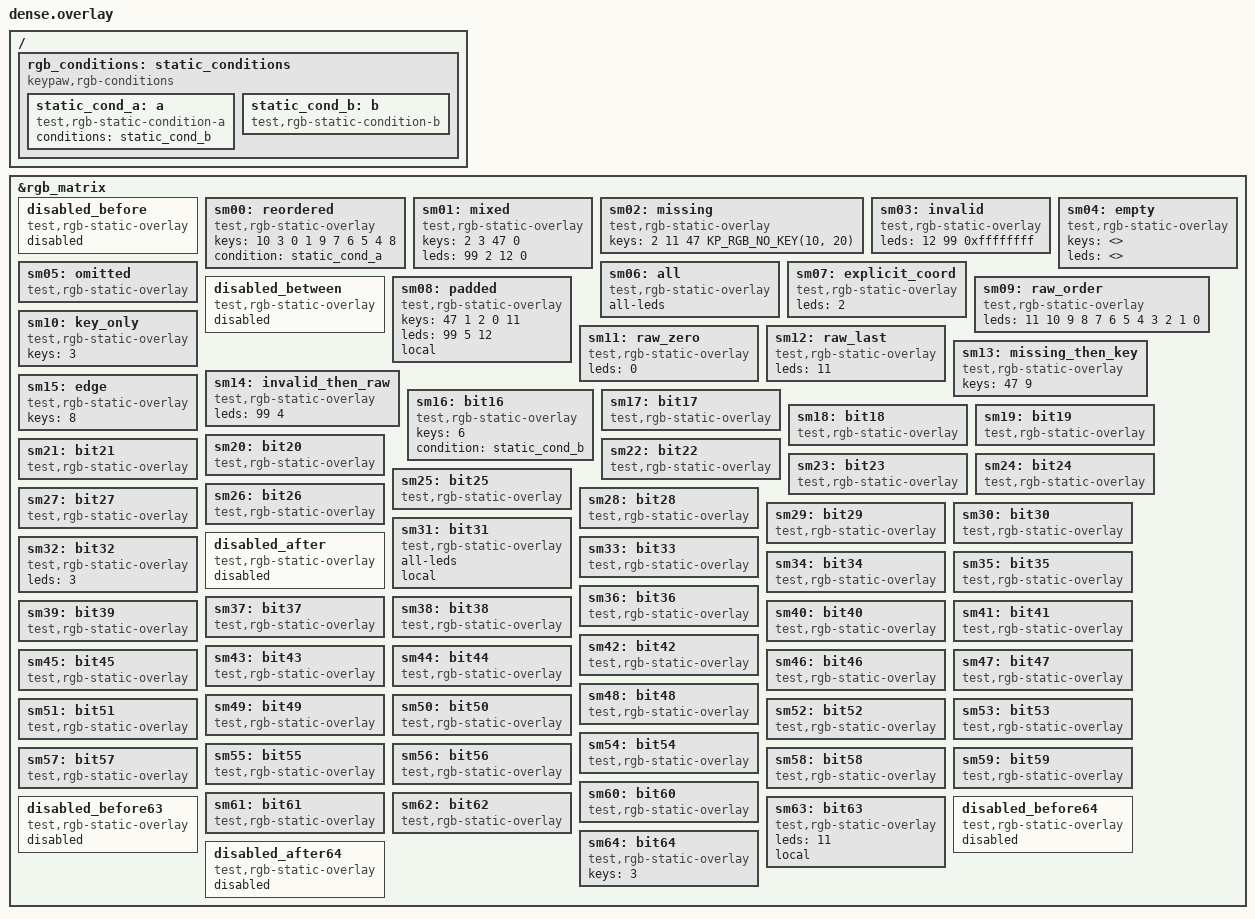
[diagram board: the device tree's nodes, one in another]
/* SPDX-License-Identifier: MIT */
#include "base.overlay"
/ {
    rgb_conditions: static_conditions {
        compatible = "keypaw,rgb-conditions";
        static_cond_a: a { compatible = "test,rgb-static-condition-a"; conditions = <&static_cond_b>; };
        static_cond_b: b { compatible = "test,rgb-static-condition-b"; };
    };
};
&rgb_matrix {
    disabled_before { compatible = "test,rgb-static-overlay"; status = "disabled"; };
    sm00: reordered { compatible = "test,rgb-static-overlay";
        keys = <10 3 0 1 9 7 6 5 4 8>; condition = <&static_cond_a>; };
    sm01: mixed { compatible = "test,rgb-static-overlay";
        keys = <2 3 47 0>; leds = <99 2 12 0>; };
    sm02: missing { compatible = "test,rgb-static-overlay"; keys = <2 11 47 KP_RGB_NO_KEY(10, 20)>; };
    sm03: invalid { compatible = "test,rgb-static-overlay"; leds = <12 99 0xffffffff>; };
    sm04: empty { compatible = "test,rgb-static-overlay"; keys = <>; leds = <>; };
    sm05: omitted { compatible = "test,rgb-static-overlay"; };
    sm06: all { compatible = "test,rgb-static-overlay"; all-leds; };
    sm07: explicit_coord { compatible = "test,rgb-static-overlay"; leds = <2>; };
    disabled_between { compatible = "test,rgb-static-overlay"; status = "disabled"; };
    sm08: padded { compatible = "test,rgb-static-overlay";
        keys = <47 1 2 0 11>; leds = <99 5 12>; local; };
    sm09: raw_order { compatible = "test,rgb-static-overlay";
        leds = <11 10 9 8 7 6 5 4 3 2 1 0>; };
    sm10: key_only { compatible = "test,rgb-static-overlay"; keys = <3>; };
    sm11: raw_zero { compatible = "test,rgb-static-overlay"; leds = <0>; };
    sm12: raw_last { compatible = "test,rgb-static-overlay"; leds = <11>; };
    sm13: missing_then_key { compatible = "test,rgb-static-overlay"; keys = <47 9>; };
    sm14: invalid_then_raw { compatible = "test,rgb-static-overlay"; leds = <99 4>; };
    sm15: edge { compatible = "test,rgb-static-overlay"; keys = <8>; };
    sm16: bit16 { compatible = "test,rgb-static-overlay";
        keys = <6>; condition = <&static_cond_b>; };
    sm17: bit17 { compatible = "test,rgb-static-overlay"; };
    sm18: bit18 { compatible = "test,rgb-static-overlay"; };
    sm19: bit19 { compatible = "test,rgb-static-overlay"; };
    sm20: bit20 { compatible = "test,rgb-static-overlay"; };
    sm21: bit21 { compatible = "test,rgb-static-overlay"; };
    sm22: bit22 { compatible = "test,rgb-static-overlay"; };
    sm23: bit23 { compatible = "test,rgb-static-overlay"; };
    sm24: bit24 { compatible = "test,rgb-static-overlay"; };
    sm25: bit25 { compatible = "test,rgb-static-overlay"; };
    sm26: bit26 { compatible = "test,rgb-static-overlay"; };
    sm27: bit27 { compatible = "test,rgb-static-overlay"; };
    sm28: bit28 { compatible = "test,rgb-static-overlay"; };
    sm29: bit29 { compatible = "test,rgb-static-overlay"; };
    sm30: bit30 { compatible = "test,rgb-static-overlay"; };
    sm31: bit31 { compatible = "test,rgb-static-overlay"; all-leds; local; };
    disabled_after { compatible = "test,rgb-static-overlay"; status = "disabled"; };
    sm32: bit32 { compatible = "test,rgb-static-overlay"; leds = <3>; };
    sm33: bit33 { compatible = "test,rgb-static-overlay"; };
    sm34: bit34 { compatible = "test,rgb-static-overlay"; };
    sm35: bit35 { compatible = "test,rgb-static-overlay"; };
    sm36: bit36 { compatible = "test,rgb-static-overlay"; };
    sm37: bit37 { compatible = "test,rgb-static-overlay"; };
    sm38: bit38 { compatible = "test,rgb-static-overlay"; };
    sm39: bit39 { compatible = "test,rgb-static-overlay"; };
    sm40: bit40 { compatible = "test,rgb-static-overlay"; };
    sm41: bit41 { compatible = "test,rgb-static-overlay"; };
    sm42: bit42 { compatible = "test,rgb-static-overlay"; };
    sm43: bit43 { compatible = "test,rgb-static-overlay"; };
    sm44: bit44 { compatible = "test,rgb-static-overlay"; };
    sm45: bit45 { compatible = "test,rgb-static-overlay"; };
    sm46: bit46 { compatible = "test,rgb-static-overlay"; };
    sm47: bit47 { compatible = "test,rgb-static-overlay"; };
    sm48: bit48 { compatible = "test,rgb-static-overlay"; };
    sm49: bit49 { compatible = "test,rgb-static-overlay"; };
    sm50: bit50 { compatible = "test,rgb-static-overlay"; };
    sm51: bit51 { compatible = "test,rgb-static-overlay"; };
    sm52: bit52 { compatible = "test,rgb-static-overlay"; };
    sm53: bit53 { compatible = "test,rgb-static-overlay"; };
    sm54: bit54 { compatible = "test,rgb-static-overlay"; };
    sm55: bit55 { compatible = "test,rgb-static-overlay"; };
    sm56: bit56 { compatible = "test,rgb-static-overlay"; };
    sm57: bit57 { compatible = "test,rgb-static-overlay"; };
    sm58: bit58 { compatible = "test,rgb-static-overlay"; };
    sm59: bit59 { compatible = "test,rgb-static-overlay"; };
    sm60: bit60 { compatible = "test,rgb-static-overlay"; };
    sm61: bit61 { compatible = "test,rgb-static-overlay"; };
    sm62: bit62 { compatible = "test,rgb-static-overlay"; };
    disabled_before63 { compatible = "test,rgb-static-overlay"; status = "disabled"; };
    sm63: bit63 { compatible = "test,rgb-static-overlay"; leds = <11>; local; };
    disabled_before64 { compatible = "test,rgb-static-overlay"; status = "disabled"; };
    sm64: bit64 { compatible = "test,rgb-static-overlay"; keys = <3>; };
    disabled_after64 { compatible = "test,rgb-static-overlay"; status = "disabled"; };
};
